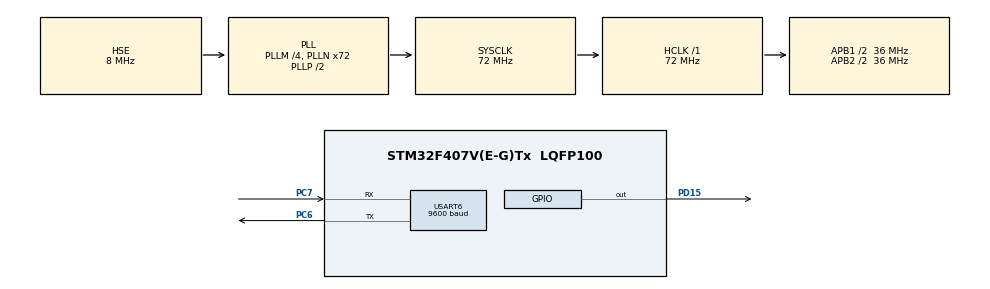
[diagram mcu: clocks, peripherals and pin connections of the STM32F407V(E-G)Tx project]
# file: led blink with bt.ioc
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Mcu.Family=STM32F4
Mcu.Name=STM32F407V(E-G)Tx
Mcu.Package=LQFP100
NVIC.PriorityGroup=NVIC_PRIORITYGROUP_0
NVIC.USART6_IRQn=true\:0\:0\:false\:false\:true\:true\:true\:true
PA13.Mode=Serial_Wire
PA13.Signal=SYS_JTMS-SWDIO
PA14.Mode=Serial_Wire
PA14.Signal=SYS_JTCK-SWCLK
PC6.Mode=Asynchronous
PC6.Signal=USART6_TX
PC7.Mode=Asynchronous
PC7.Signal=USART6_RX
PD15.Signal=GPIO_Output
PH0-OSC_IN.Mode=HSE-External-Oscillator
PH0-OSC_IN.Signal=RCC_OSC_IN
PH1-OSC_OUT.Mode=HSE-External-Oscillator
PH1-OSC_OUT.Signal=RCC_OSC_OUT
ProjectManager.HeapSize=0x200
ProjectManager.StackSize=0x400
ProjectManager.TargetToolchain=STM32CubeIDE
RCC.48MHZClocksFreq_Value=20571428.57142857
RCC.AHBFreq_Value=72000000
RCC.APB1CLKDivider=RCC_HCLK_DIV2
RCC.APB1Freq_Value=36000000
RCC.APB1TimFreq_Value=72000000
RCC.APB2CLKDivider=RCC_HCLK_DIV2
RCC.APB2Freq_Value=36000000
RCC.APB2TimFreq_Value=72000000
RCC.CortexFreq_Value=72000000
RCC.HCLKFreq_Value=72000000
RCC.HSE_VALUE=8000000
RCC.HSI_VALUE=16000000
RCC.LSE_VALUE=32768
RCC.PLLM=4
RCC.PLLN=72
RCC.PLLQ=7
RCC.PLLSourceVirtual=RCC_PLLSOURCE_HSE
RCC.SYSCLKFreq_VALUE=72000000
RCC.SYSCLKSource=RCC_SYSCLKSOURCE_PLLCLK
RCC.VCOOutputFreq_Value=144000000
USART6.BaudRate=9600
USART6.VirtualMode=VM_ASYNC
board=STM32F407G-DISC1

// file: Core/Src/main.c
/* USER CODE BEGIN Header */
/**
  ******************************************************************************
  * @file           : main.c
  * @brief          : Main program body
  ******************************************************************************
  * @attention
  *
  * <h2><center>&copy; Copyright (c) 2024 STMicroelectronics.
  * All rights reserved.</center></h2>
  *
  * This software component is licensed by ST under Ultimate Liberty license
  * SLA0044, the "License"; You may not use this file except in compliance with
  * the License. You may obtain a copy of the License at:
  *                             www.st.com/SLA0044
  *
  ******************************************************************************
  */
/* USER CODE END Header */
#include "main.h"

UART_HandleTypeDef huart6;
uint8_t rxData;

void SystemClock_Config(void);
static void MX_GPIO_Init(void);
static void MX_USART6_UART_Init(void);

int main(void)
{

  /* MCU Configuration--------------------------------------------------------*/

  /* Reset of all peripherals, Initializes the Flash interface and the Systick. */
  HAL_Init();

  /* Configure the system clock */
  SystemClock_Config();

  /* Initialize all configured peripherals */
  MX_GPIO_Init();
  MX_USART6_UART_Init();
  /* USER CODE BEGIN 2 */
  HAL_UART_Receive_IT(&huart6,&rxData,1);
  /* USER CODE END 2 */

  /* Infinite loop */
  while (1)
  {

  }
}
void HAL_UART_RxCpltCallback(UART_HandleTypeDef *huart)
{
	if (huart -> Instance == USART6)
	{
		if(rxData == 79) //ascii value of 'O' : on
		{
			HAL_GPIO_WritePin (GPIOD, GPIO_PIN_15, 1);// allumer la led bleue
		}
		else if (rxData ==88)// ascii value of 'X' : off
		{
			HAL_GPIO_WritePin (GPIOD, GPIO_PIN_15, 0);// atteindre la led bleue
		}
		 HAL_UART_Receive_IT(&huart6,&rxData,1);// enabling interrupt receive again
	}
}
void SystemClock_Config(void)
{
  RCC_OscInitTypeDef RCC_OscInitStruct = {0};
  RCC_ClkInitTypeDef RCC_ClkInitStruct = {0};

  /** Configure the main internal regulator output voltage
  */
  __HAL_RCC_PWR_CLK_ENABLE();
  __HAL_PWR_VOLTAGESCALING_CONFIG(PWR_REGULATOR_VOLTAGE_SCALE1);

  /** Initializes the RCC Oscillators according to the specified parameters
  * in the RCC_OscInitTypeDef structure.
  */
  RCC_OscInitStruct.OscillatorType = RCC_OSCILLATORTYPE_HSE;
  RCC_OscInitStruct.HSEState = RCC_HSE_ON;
  RCC_OscInitStruct.PLL.PLLState = RCC_PLL_ON;
  RCC_OscInitStruct.PLL.PLLSource = RCC_PLLSOURCE_HSE;
  RCC_OscInitStruct.PLL.PLLM = 4;
  RCC_OscInitStruct.PLL.PLLN = 72;
  RCC_OscInitStruct.PLL.PLLP = RCC_PLLP_DIV2;
  RCC_OscInitStruct.PLL.PLLQ = 7;
  if (HAL_RCC_OscConfig(&RCC_OscInitStruct) != HAL_OK)
  {
    Error_Handler();
  }

  /** Initializes the CPU, AHB and APB buses clocks
  */
  RCC_ClkInitStruct.ClockType = RCC_CLOCKTYPE_HCLK|RCC_CLOCKTYPE_SYSCLK
                              |RCC_CLOCKTYPE_PCLK1|RCC_CLOCKTYPE_PCLK2;
  RCC_ClkInitStruct.SYSCLKSource = RCC_SYSCLKSOURCE_PLLCLK;
  RCC_ClkInitStruct.AHBCLKDivider = RCC_SYSCLK_DIV1;
  RCC_ClkInitStruct.APB1CLKDivider = RCC_HCLK_DIV2;
  RCC_ClkInitStruct.APB2CLKDivider = RCC_HCLK_DIV2;

  if (HAL_RCC_ClockConfig(&RCC_ClkInitStruct, FLASH_LATENCY_2) != HAL_OK)
  {
    Error_Handler();
  }
}

static void MX_USART6_UART_Init(void)
{

  huart6.Instance = USART6;
  huart6.Init.BaudRate = 9600;
  huart6.Init.WordLength = UART_WORDLENGTH_8B;
  huart6.Init.StopBits = UART_STOPBITS_1;
  huart6.Init.Parity = UART_PARITY_NONE;
  huart6.Init.Mode = UART_MODE_TX_RX;
  huart6.Init.HwFlowCtl = UART_HWCONTROL_NONE;
  huart6.Init.OverSampling = UART_OVERSAMPLING_16;
  if (HAL_UART_Init(&huart6) != HAL_OK)
  {
    Error_Handler();
  }

}

static void MX_GPIO_Init(void)
{
  GPIO_InitTypeDef GPIO_InitStruct = {0};

  /* GPIO Ports Clock Enable */
  __HAL_RCC_GPIOH_CLK_ENABLE();
  __HAL_RCC_GPIOD_CLK_ENABLE();
  __HAL_RCC_GPIOC_CLK_ENABLE();
  __HAL_RCC_GPIOA_CLK_ENABLE();

  /*Configure GPIO pin Output Level */
  HAL_GPIO_WritePin(GPIOD, GPIO_PIN_15, GPIO_PIN_RESET);

  /*Configure GPIO pin : PD15 */
  GPIO_InitStruct.Pin = GPIO_PIN_15;
  GPIO_InitStruct.Mode = GPIO_MODE_OUTPUT_PP;
  GPIO_InitStruct.Pull = GPIO_NOPULL;
  GPIO_InitStruct.Speed = GPIO_SPEED_FREQ_LOW;
  HAL_GPIO_Init(GPIOD, &GPIO_InitStruct);

}

void Error_Handler(void)
{
  __disable_irq();
  while (1)
  {
  }
}
